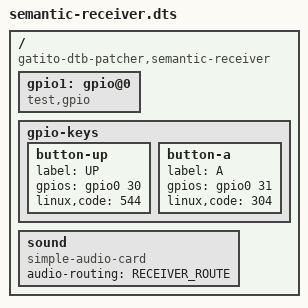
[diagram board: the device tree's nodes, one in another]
/dts-v1/;

/ {
    compatible = "gatito-dtb-patcher,semantic-receiver";

    gpio1: gpio@0 {
        phandle = <7>;
        compatible = "test,gpio";
        #gpio-cells = <2>;
    };

    gpio-keys {
        button-up {
            label = "UP";
            gpios = <&gpio0 30 0>;
            linux,code = <544>;
        };

        button-a {
            label = "A";
            gpios = <&gpio0 31 0>;
            linux,code = <304>;
        };
    };

    sound {
        compatible = "simple-audio-card";
        audio-routing = "RECEIVER_ROUTE";
    };
};
